# STM32WBA25 register map
File version: 1.0
CPU: CM33 r0p1, little endian, MPU, FPU, 4 interrupt priority bits
Registers are 32-bit, read-write, reset 0x0 unless marked. A register's access mark holds for its fields unless they carry their own. Offsets are from the block's base; [hi:lo] are bit positions; {n}, {i} and the like mark numbered series; 'fields as' and 'values as' point back to an identical list.

## USB — USB address block description
Base 0x40016000
Same registers: USBSRAM 0x40016400, SEC_USB 0x50016000, SEC_USBSRAM 0x50016400
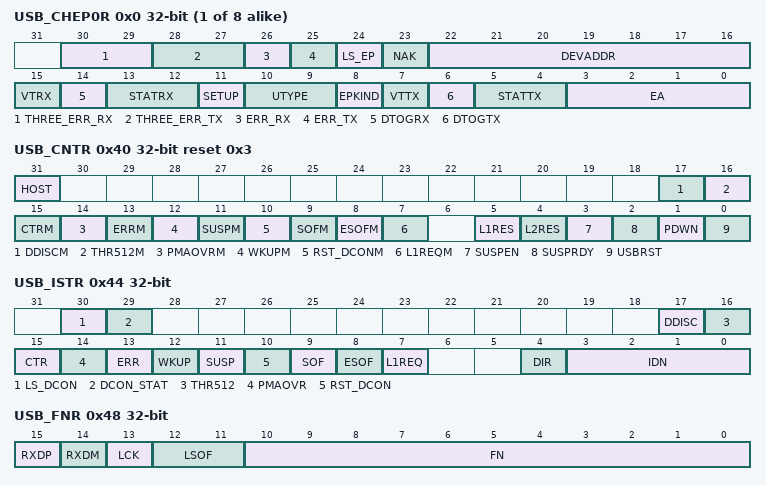
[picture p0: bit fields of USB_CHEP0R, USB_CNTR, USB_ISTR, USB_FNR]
{0x0+4i} USB_CHEP{i}R (i=0..7) — USB endpoint/channel {i} register
  [30:29] THREE_ERR_RX — Three errors for an IN transaction
    0=Less than 3 errors received; 1=More than 3 errors received, last error is timeout error; 2=More than 3 errors received, last error is data error (CRC error); 3=More than 3 errors received, last error is protocol error (invalid PID, false EOP, bitstuffing error, SYNC error)
  [28:27] THREE_ERR_TX — Three errors for an OUT or SETUP transaction
    values as THREE_ERR_RX
  [26] ERR_RX — Received error for an IN transaction
  [25] ERR_TX — Received error for an OUT/SETUP transaction
  [24] LS_EP — Low speed endpoint host with HUB only
    0=Full speed endpoint; 1=Low speed endpoint
  [23] NAK — Host mode
  [22:16] DEVADDR — Host mode
  [15] VTRX — USB valid transaction received
  [14] DTOGRX wo — Data Toggle, for reception transfers
  [13:12] STATRX wo — Status bits, for reception transfers
  [11] SETUP ro — Setup transaction completed
  [10:9] UTYPE — USB type of transaction
  [8] EPKIND — endpoint/channel kind
  [7] VTTX — Valid USB transaction transmitted
  [6] DTOGTX wo — Data toggle, for transmission transfers
  [5:4] STATTX wo — Status bits, for transmission transfers
  [3:0] EA — endpoint/channel address
0x40 USB_CNTR reset 0x3 — USB control register
  [31] HOST — HOST mode
    0=USB Device function; 1=USB host function
  [17] DDISCM — Device disconnection mask
    0=Device disconnection interrupt disabled; 1=Device disconnection interrupt enabled
  [16] THR512M — 512 byte threshold interrupt mask
    0=512 byte threshold interrupt disabled; 1=512 byte threshold interrupt enabled
  [15] CTRM — Correct transfer interrupt mask
    0=Correct transfer (CTR) interrupt disabled; 1=CTR interrupt enabled, an interrupt request is generated when the corresponding bit in the USB_ISTR register is set
  [14] PMAOVRM — Packet memory area over / underrun interrupt mask
    0=PMAOVR interrupt disabled; 1=PMAOVR interrupt enabled, an interrupt request is generated when the corresponding bit in the USB_ISTR register is set
  [13] ERRM — Error interrupt mask
    0=ERR interrupt disabled; 1=ERR interrupt enabled, an interrupt request is generated when the corresponding bit in the USB_ISTR register is set
  [12] WKUPM — Wake-up interrupt mask
    0=WKUP interrupt disabled; 1=WKUP interrupt enabled, an interrupt request is generated when the corresponding bit in the USB_ISTR register is set
  [11] SUSPM — Suspend mode interrupt mask
    0=Suspend mode request (SUSP) interrupt disabled; 1=SUSP interrupt enabled, an interrupt request is generated when the corresponding bit in the USB_ISTR register is set
  [10] RST_DCONM — USB reset request (Device mode) or device connect/disconnect (Host mode) interrupt mask
    0=RESET interrupt disabled; 1=RESET interrupt enabled, an interrupt request is generated when the corresponding bit in the USB_ISTR register is set
  [9] SOFM — Start of frame interrupt mask
    0=SOF interrupt disabled; 1=SOF interrupt enabled, an interrupt request is generated when the corresponding bit in the USB_ISTR register is set
  [8] ESOFM — Expected start of frame interrupt mask
    0=Expected start of frame (ESOF) interrupt disabled; 1=ESOF interrupt enabled, an interrupt request is generated when the corresponding bit in the USB_ISTR register is set
  [7] L1REQM — LPM L1 state request interrupt mask
    0=LPM L1 state request (L1REQ) interrupt disabled; 1=L1REQ interrupt enabled, an interrupt request is generated when the corresponding bit in the USB_ISTR register is set
  [5] L1RES — L1 remote wake-up / resume driver
    0=No effect; 1=Send 50us remote-wake-up signaling to host
  [4] L2RES — L2 remote wake-up / resume driver
    0=No effect; 1=Send L2 resume signaling to device
  [3] SUSPEN — Suspend state enable
    0=B_0x0_DEVICE_MODE (No effect); 1=B_0x1_DEVICE_MODE (Enter L1/L2 suspend)
  [2] SUSPRDY ro — Suspend state effective
    0=Normal operation; 1=Suspend state
  [1] PDWN — Power down
    0=Exit power down; 1=Enter power down mode
  [0] USBRST — USB Reset
    0=B_0x0_DEVICE_MODE (No effect); 1=B_0x1_DEVICE_MODE (USB core is under reset)
0x44 USB_ISTR — USB interrupt status register
  [30] LS_DCON ro — Low speed device connected
  [29] DCON_STAT ro — Device connection status
    0=No device connected; 1=FS or LS device connected to the host
  [17] DDISC — Device connection
  [16] THR512 — 512 byte threshold interrupt
  [15] CTR ro — Completed transfer in host mode
  [14] PMAOVR — Packet memory area over / underrun
  [13] ERR — Error
  [12] WKUP — Wake-up
  [11] SUSP — Suspend mode request
  [10] RST_DCON — USB reset request (Device mode) or device connect/disconnect (Host mode)
  [9] SOF — Start of frame
  [8] ESOF — Expected start of frame
  [7] L1REQ — LPM L1 state request
  [4] DIR ro — Direction of transaction
  [3:0] IDN ro — Device Endpoint / host channel identification number
0x48 USB_FNR ro (reset mask 0xFFFFF000) — USB frame number register
  [15] RXDP — Receive data + line status
  [14] RXDM — Receive data - line status
  [13] LCK — Locked
  [12:11] LSOF — Lost SOF
  [10:0] FN — Frame number
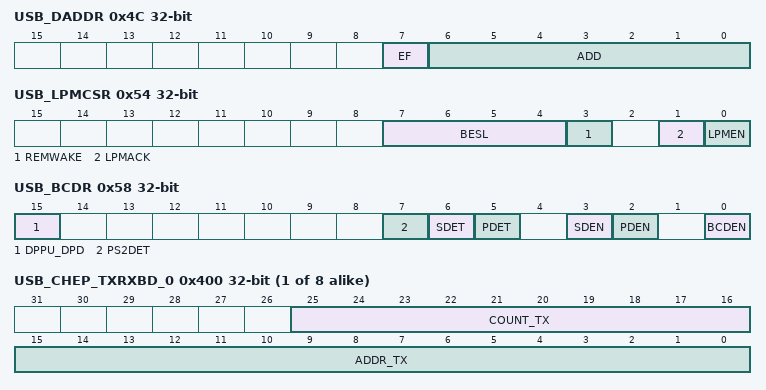
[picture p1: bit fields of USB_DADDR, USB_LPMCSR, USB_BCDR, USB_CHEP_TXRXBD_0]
0x4C USB_DADDR — USB Device address
  [7] EF — Enable function
  [6:0] ADD — Device address
0x54 USB_LPMCSR — LPM control and status register
  [7:4] BESL ro — BESL value
  [3] REMWAKE ro — bRemoteWake value
  [1] LPMACK — LPM token acknowledge enable
    0=the valid LPM token is NYET; 1=the valid LPM token is ACK
  [0] LPMEN — LPM support enable
0x58 USB_BCDR — Battery charging detector
  [15] DPPU_DPD — DP pull-up / DPDM pull-down
  [7] PS2DET ro — DM pull-up detection status
    0=Normal port detected (connected to SDP, ACA, CDP or DCP); 1=PS2 port or proprietary charger detected
  [6] SDET ro — Secondary detection (SD) status
    0=CDP detected; 1=DCP detected
  [5] PDET ro — Primary detection (PD) status
    0=no BCD support detected (connected to SDP or proprietary device); 1=BCD support detected (connected to ACA, CDP or DCP)
  [3] SDEN — Secondary detection (SD) mode enable
  [2] PDEN — Primary detection (PD) mode enable
  [0] BCDEN — Battery charging detector (BCD) enable
{0x400+8i} USB_CHEP_TXRXBD_{i} reset not defined (i=0..7) — Channel/endpoint transmit buffer descriptor {i}
  [25:16] COUNT_TX — Transmission byte count
  [15:0] ADDR_TX — Transmission buffer address
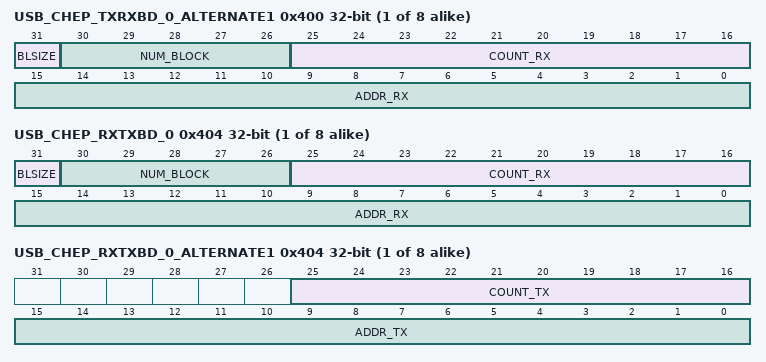
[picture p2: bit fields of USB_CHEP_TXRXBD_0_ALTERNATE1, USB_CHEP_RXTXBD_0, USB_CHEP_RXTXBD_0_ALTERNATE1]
{0x400+8i} USB_CHEP_TXRXBD_{i}_ALTERNATE1 reset not defined (alternate view of USB_CHEP_TXRXBD_{i}) (i=0..7) — Channel/endpoint receive buffer descriptor {i}
  [31] BLSIZE — Block size
  [30:26] NUM_BLOCK — Number of blocks
  [25:16] COUNT_RX ro — Reception byte count
  [15:0] ADDR_RX — Reception buffer address
{0x404+8i} USB_CHEP_RXTXBD_{i} reset not defined (i=0..7) — Channel/endpoint receive buffer descriptor {i}
  fields as USB_CHEP_TXRXBD_0_ALTERNATE1
{0x404+8i} USB_CHEP_RXTXBD_{i}_ALTERNATE1 reset not defined (alternate view of USB_CHEP_RXTXBD_{i}) (i=0..7) — Channel/endpoint transmit buffer descriptor {i}
  fields as USB_CHEP_TXRXBD_0
